# STM32G554 register map
File version: 2.0.0
CPU: CM33 r0p4, little endian, MPU, FPU, 4 interrupt priority bits
Registers are 32-bit, read-write, reset 0x0 unless marked. A register's access mark holds for its fields unless they carry their own. Offsets are from the block's base; [hi:lo] are bit positions; 'fields as' and 'values as' point back to an identical list.

## FDCAN1 — FDCAN register block
Base 0x4000A000
Same registers: FDCAN2 0x4000A400, FDCAN3 0x4000A800, FDCAN1_S 0x5000A000, FDCAN2_S 0x5000A400, FDCAN3_S 0x5000A800
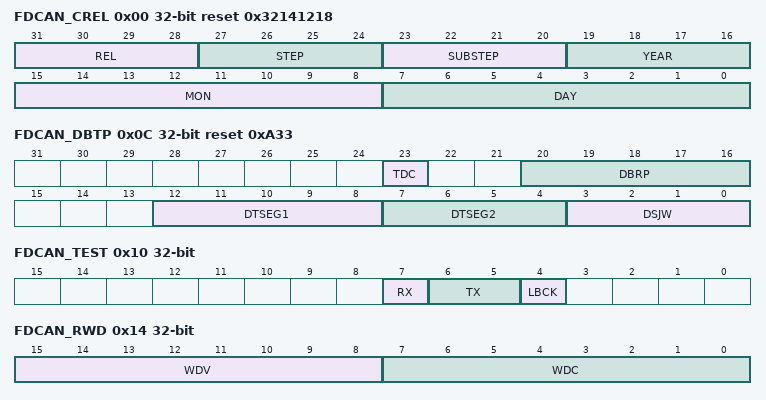
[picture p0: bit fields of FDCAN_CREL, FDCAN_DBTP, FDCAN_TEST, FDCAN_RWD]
0x00 FDCAN_CREL ro reset 0x32141218 — FDCAN core release register
  [31:28] REL — 3
  [27:24] STEP — 2
  [23:20] SUBSTEP — 1
  [19:16] YEAR — 4
  [15:8] MON — 12
  [7:0] DAY — 18
0x04 FDCAN_ENDN ro reset 0x87654321 — FDCAN endian register
  [31:0] ETV — Endianness test value
0x0C FDCAN_DBTP reset 0xA33 — FDCAN data bit timing and prescaler register
  [23] TDC — Transceiver delay compensation
    0=Transceiver delay compensation disabled; 1=Transceiver delay compensation enabled
  [20:16] DBRP — Data bit rate prescaler
  [12:8] DTSEG1 — Data time segment before sample point
  [7:4] DTSEG2 — Data time segment after sample point
  [3:0] DSJW — Synchronization jump width
0x10 FDCAN_TEST
  [7] RX ro — Receive pin
    0=The CAN bus is dominant (FDCANx_RX=0); 1=The CAN bus is recessive (FDCANx_RX=1)
  [6:5] TX — Control of transmit pin
    0=Reset value, FDCANx_TX TX is controlled by the CAN core, updated at the end of the CAN bit time; 1=Sample point can be monitored at pin FDCANx_TX; 2=Dominant (0) level at pin FDCANx_TX; 3=Recessive (1) at pin FDCANx_TX
  [4] LBCK — Loop-back mode
    0=Reset value, loop-back mode is disabled; 1=Loop-back mode is enabled (see Power-down (Sleep mode))
0x14 FDCAN_RWD — FDCAN RAM watchdog register
  [15:8] WDV ro — Watchdog value
  [7:0] WDC — Watchdog configuration
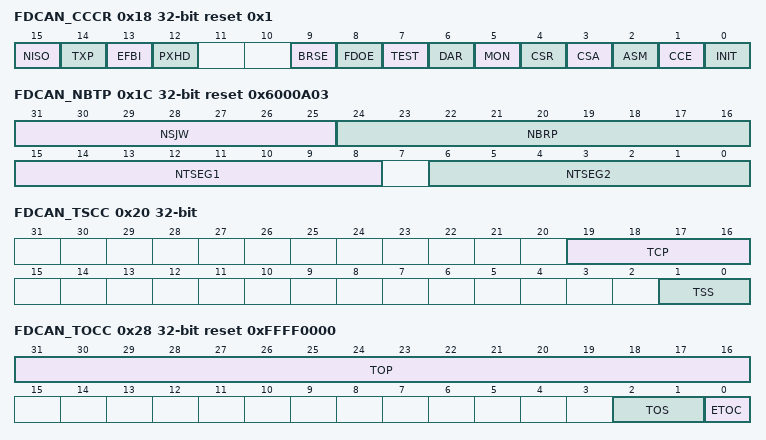
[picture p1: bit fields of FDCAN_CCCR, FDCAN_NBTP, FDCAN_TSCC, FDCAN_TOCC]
0x18 FDCAN_CCCR reset 0x1 — FDCAN CC control register
  [15] NISO — Non-ISO operation
    0=CAN FD frame format according to ISO11898-1; 1=CAN FD frame format according to Bosch CAN FD Specification V1.0
  [14] TXP — Transmit pause enable
    0=Disabled; 1=Enabled
  [13] EFBI — Edge filtering during bus integration
    0=Edge filtering disabled; 1=Two consecutive dominant tless thansub>qless than/sub> required to detect an edge for hard synchronization
  [12] PXHD — Protocol exception handling disable
    0=Protocol exception handling enabled; 1=Protocol exception handling disabled
  [9] BRSE — FDCAN bit rate switching
    0=Bit rate switching for transmissions disabled; 1=Bit rate switching for transmissions enabled
  [8] FDOE — FD operation enable
    0=FD operation disabled; 1=FD operation enabled
  [7] TEST — Test mode enable
    0=Normal operation, FDCAN_TEST holds reset values; 1=Test mode, write access to FDCAN_TEST enabled
  [6] DAR — Disable automatic retransmission
    0=Automatic retransmission of messages not transmitted successfully enabled; 1=Automatic retransmission disabled
  [5] MON — Bus monitoring mode
    0=Bus monitoring mode disabled; 1=Bus monitoring mode enabled
  [4] CSR — Clock stop request
    0=No clock stop requested; 1=Clock stop requested. When clock stop is requested, first INIT and then CSA is set after all pending transfer requests have been completed and the CAN bus is idle.
  [3] CSA ro — Clock stop acknowledge
    0=No clock stop acknowledged; 1=FDCAN can be set in power-down by stopping APB clock and kernel clock
  [2] ASM — ASM restricted operation mode
    0=Normal CAN operation; 1=Restricted operation mode active
  [1] CCE — Configuration change enable
    0=The CPU has no write access to the protected configuration registers; 1=The CPU has write access to the protected configuration registers (while INIT set in FDCAN_CCCR)
  [0] INIT — Initialization
    0=Normal operation; 1=Initialization started
0x1C FDCAN_NBTP reset 0x6000A03 — FDCAN nominal bit timing and prescaler register
  [31:25] NSJW — Nominal (re)synchronization jump width
  [24:16] NBRP — Bit rate prescaler
  [15:8] NTSEG1 — Nominal time segment before sample point
  [6:0] NTSEG2 — Nominal time segment after sample point
0x20 FDCAN_TSCC — FDCAN timestamp counter configuration register
  [19:16] TCP — Timestamp counter prescaler
  [1:0] TSS — Timestamp select
    0=Timestamp counter value always 0x0000; 1=Timestamp counter value incremented according to TCP; 2=External timestamp counter from TIM2 value (tim2_cnt[15:0]); 3=Same as 00
0x24 FDCAN_TSCV — FDCAN timestamp counter value register
  [15:0] TSC — Timestamp counter
0x28 FDCAN_TOCC reset 0xFFFF0000 — FDCAN timeout counter configuration register
  [31:16] TOP — Timeout period
  [2:1] TOS — Timeout select
    0=Continuous operation; 1=Timeout controlled by Tx event FIFO; 2=Timeout controlled by Rx FIFO 0; 3=Timeout controlled by Rx FIFO 1
  [0] ETOC — Timeout counter enable
    0=Timeout counter disabled; 1=Timeout counter enabled
0x2C FDCAN_TOCV reset 0xFFFF — FDCAN timeout counter value register
  [15:0] TOC — Timeout counter
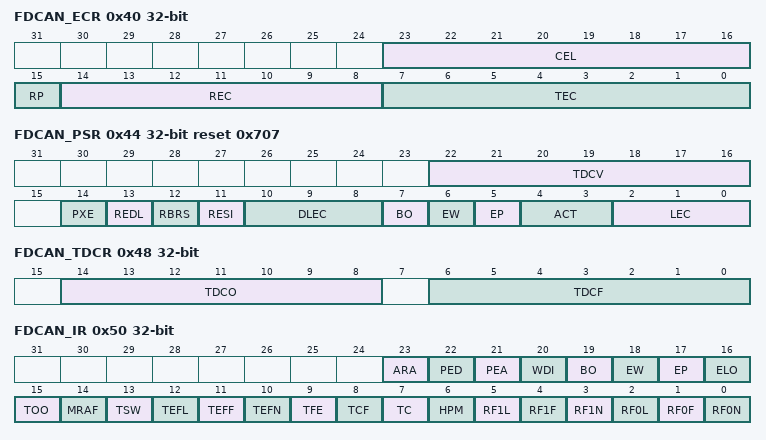
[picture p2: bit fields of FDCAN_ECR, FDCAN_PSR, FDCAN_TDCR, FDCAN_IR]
0x40 FDCAN_ECR — FDCAN error counter register
  [23:16] CEL — CAN error logging
  [15] RP ro — Receive error passive
    0=The receive error counter is below the error passive level of 128; 1=The receive error counter has reached the error passive level of 128
  [14:8] REC ro — Receive error counter
  [7:0] TEC ro — Transmit error counter
0x44 FDCAN_PSR reset 0x707 — FDCAN protocol status register
  [22:16] TDCV ro — Transmitter delay compensation value
  [14] PXE — Protocol exception event
    0=No protocol exception event occurred since last read access; 1=Protocol exception event occurred
  [13] REDL — Received FDCAN message
    0=Since this bit was cleared by the CPU, no FDCAN message has been received; 1=Message in FDCAN format with EDL flag set has been received
  [12] RBRS — BRS flag of last received FDCAN message
    0=Last received FDCAN message did not have its BRS flag set; 1=Last received FDCAN message had its BRS flag set
  [11] RESI — ESI flag of last received FDCAN message
    0=Last received FDCAN message did not have its ESI flag set; 1=Last received FDCAN message had its ESI flag set
  [10:8] DLEC — Data last error code
  [7] BO ro — Bus-off status
    0=The FDCAN is not in bus-off state; 1=The FDCAN is in bus-off state
  [6] EW ro — Warning status
    0=Both error counters are below the error-warning limit of 96; 1=At least one of error counter has reached the error-warning limit of 96
  [5] EP ro — Error passive
    0=The FDCAN is in the error-active state. It normally takes part in bus communication and sends an active error flag when an error has been detected.; 1=The FDCAN is in the error-passive state
  [4:3] ACT ro — Activity
    0=Synchronizing: node is synchronizing on CAN communication; 1=Idle: node is neither receiver nor transmitter; 2=Receiver: node is operating as receiver; 3=Transmitter: node is operating as transmitter
  [2:0] LEC — Last error code
    0=No error occurred since LEC[2:0] has been cleared by successful reception or transmission; 1=Stuff error. More than five equal bits in a sequence have occurred in a part of a received message where this is not allowed.; 2=Form error. A fixed format part of a received frame has the wrong format.; 3=Ack error. The message transmitted by the FDCAN was not acknowledged by another node.; 4=Bit1 error. During the transmission of a message (with the exception of the arbitration field), the device wanted to send a recessive level (bit of logical value 1), but the monitored bus value was dominant.; 5=Bit0 error. During the transmission of a message (or acknowledge bit, or active error flag, or overload flag), the device wanted to send a dominant level (data or identifier bit logical value 0), but the monitored bus value was recessive. During bus-off recovery this status is set each time a sequence of 11 recessive bits has been monitored. This enables the CPU to monitor the proceeding of the bus-off recovery sequence (indicating the bus is not stuck at dominant or continuously disturbed).; 6=CRC error. The CRC check sum of a received message was incorrect. The CRC of an incoming message does not match with the CRC calculated from the received data.; 7=No change. Any read access to the protocol status register reinitializes LEC[2:0] to 7. When the LEC[2:0] shows the value 7, no CAN bus event was detected since the last CPU read access to the protocol status register.
0x48 FDCAN_TDCR — FDCAN transmitter delay compensation register
  [14:8] TDCO — Transmitter delay compensation offset
  [6:0] TDCF — Transmitter delay compensation filter window length
0x50 FDCAN_IR — FDCAN interrupt register
  [23] ARA — Access to reserved address
    0=No access to reserved address occurred; 1=Access to reserved address occurred
  [22] PED — Protocol error in data phase (data bit time is used)
    0=No protocol error in data phase; 1=Protocol error in data phase detected (DLEC[2:0] different from 0 and 7 in FDCAN_PSR)
  [21] PEA — Protocol error in arbitration phase (nominal bit time is used)
    0=No protocol error in arbitration phase; 1=Protocol error in arbitration phase detected (LEC[2:0] different from 0 and 7 in FDCAN_PSR)
  [20] WDI — Watchdog interrupt
    0=No message RAM watchdog event occurred; 1=Message RAM watchdog event due to missing READY
  [19] BO — Bus-off status
    0=Bus-off status unchanged; 1=Bus-off status changed
  [18] EW — Warning status
    0=Error-warning status unchanged; 1=Error-warning status changed
  [17] EP — Error passive
    0=Error-passive status unchanged; 1=Error-passive status changed
  [16] ELO — Error logging overflow
    0=CAN error logging counter did not overflow; 1=Overflow of CAN error logging counter occurred
  [15] TOO — Timeout occurred
    0=No timeout; 1=Timeout reached
  [14] MRAF — Message RAM access failure
    0=No message RAM access failure occurred; 1=Message RAM access failure occurred
  [13] TSW — Timestamp wraparound
    0=No timestamp counter wrap-around; 1=Timestamp counter wrapped around
  [12] TEFL — Tx event FIFO element lost
    0=No Tx event FIFO element lost; 1=Tx event FIFO element lost
  [11] TEFF — Tx event FIFO full
    0=Tx event FIFO Not full; 1=Tx event FIFO full
  [10] TEFN — Tx event FIFO new entry
    0=Tx event FIFO unchanged; 1=Tx handler wrote Tx event FIFO element
  [9] TFE — Tx FIFO empty
    0=Tx FIFO non-empty; 1=Tx FIFO empty
  [8] TCF — Transmission cancellation finished
    0=No transmission cancellation finished; 1=Transmission cancellation finished
  [7] TC — Transmission completed
    0=No transmission completed; 1=Transmission completed
  [6] HPM — High-priority message
    0=No high-priority message received; 1=High-priority message received
  [5] RF1L — Rx FIFO 1 message lost
    0=No Rx FIFO 1 message lost; 1=Rx FIFO 1 message lost
  [4] RF1F — Rx FIFO 1 full
    0=Rx FIFO 1 not full; 1=Rx FIFO 1 full
  [3] RF1N — Rx FIFO 1 new message
    0=No new message written to Rx FIFO 1; 1=New message written to Rx FIFO 1
  [2] RF0L — Rx FIFO 0 message lost
    0=No Rx FIFO 0 message lost; 1=Rx FIFO 0 message lost
  [1] RF0F — Rx FIFO 0 full
    0=Rx FIFO 0 not full; 1=Rx FIFO 0 full
  [0] RF0N — Rx FIFO 0 new message
    0=No new message written to Rx FIFO 0; 1=New message written to Rx FIFO 0
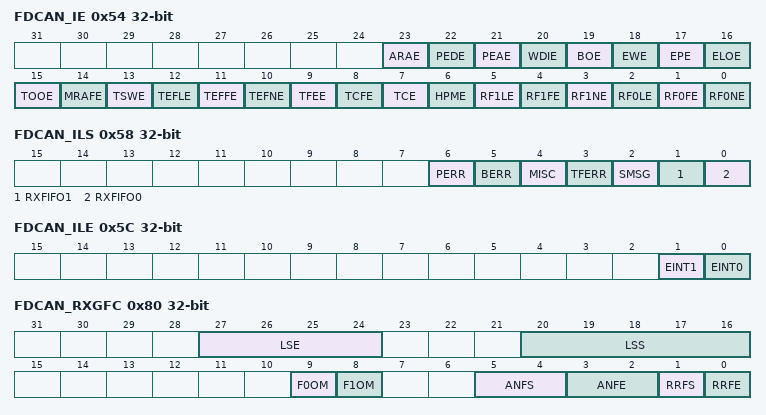
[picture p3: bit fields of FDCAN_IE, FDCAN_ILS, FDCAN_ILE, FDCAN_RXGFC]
0x54 FDCAN_IE — FDCAN interrupt enable register
  [23] ARAE — Access to reserved address enable
  [22] PEDE — Protocol error in data phase enable
  [21] PEAE — Protocol error in arbitration phase enable
  [20] WDIE — Watchdog interrupt enable
    0=Interrupt disabled; 1=Interrupt enabled
  [19] BOE — Bus-off status
    0=Interrupt disabled; 1=Interrupt enabled
  [18] EWE — Warning status interrupt enable
    0=Interrupt disabled; 1=Interrupt enabled
  [17] EPE — Error passive interrupt enable
    0=Interrupt disabled; 1=Interrupt enabled
  [16] ELOE — Error logging overflow interrupt enable
    0=Interrupt disabled; 1=Interrupt enabled
  [15] TOOE — Timeout occurred interrupt enable
    0=Interrupt disabled; 1=Interrupt enabled
  [14] MRAFE — Message RAM access failure interrupt enable
    0=Interrupt disabled; 1=Interrupt enabled
  [13] TSWE — Timestamp wraparound interrupt enable
    0=Interrupt disabled; 1=Interrupt enabled
  [12] TEFLE — Tx event FIFO element lost interrupt enable
    0=Interrupt disabled; 1=Interrupt enabled
  [11] TEFFE — Tx event FIFO full interrupt enable
    0=Interrupt disabled; 1=Interrupt enabled
  [10] TEFNE — Tx event FIFO new entry interrupt enable
    0=Interrupt disabled; 1=Interrupt enabled
  [9] TFEE — Tx FIFO empty interrupt enable
    0=Interrupt disabled; 1=Interrupt enabled
  [8] TCFE — Transmission cancellation finished interrupt enable
    0=Interrupt disabled; 1=Interrupt enabled
  [7] TCE — Transmission completed interrupt enable
    0=Interrupt disabled; 1=Interrupt enabled
  [6] HPME — High-priority message interrupt enable
    0=Interrupt disabled; 1=Interrupt enabled
  [5] RF1LE — Rx FIFO 1 message lost interrupt enable
    0=Interrupt disabled; 1=Interrupt enabled
  [4] RF1FE — Rx FIFO 1 full interrupt enable
    0=Interrupt disabled; 1=Interrupt enabled
  [3] RF1NE — Rx FIFO 1 new message interrupt enable
    0=Interrupt disabled; 1=Interrupt enabled
  [2] RF0LE — Rx FIFO 0 message lost interrupt enable
    0=Interrupt disabled; 1=Interrupt enabled
  [1] RF0FE — Rx FIFO 0 full interrupt enable
    0=Interrupt disabled; 1=Interrupt enabled
  [0] RF0NE — Rx FIFO 0 new message interrupt enable
    0=Interrupt disabled; 1=Interrupt enabled
0x58 FDCAN_ILS — FDCAN interrupt line select register
  [6] PERR — Protocol error grouping the following interruption
  [5] BERR — Bit and line error grouping the following interruption
  [4] MISC — Interrupt regrouping the following interruption
  [3] TFERR — Tx FIFO ERROR grouping the following interruption
  [2] SMSG — Status message bit grouping the following interruption
  [1] RXFIFO1 — RX FIFO bit grouping the following interruption
  [0] RXFIFO0 — RX FIFO bit grouping the following interruption
0x5C FDCAN_ILE — FDCAN interrupt line enable register
  [1] EINT1 — Enable interrupt line 1
    0=Interrupt line fdcan_intr0_it disabled; 1=Interrupt line fdcan_intr0_it enabled
  [0] EINT0 — Enable interrupt line 0
    0=Interrupt line fdcan_intr1_it disabled; 1=Interrupt line fdcan_intr1_it enabled
0x80 FDCAN_RXGFC — FDCAN global filter configuration register
  [27:24] LSE — Number of extended filter elements in the list
    0=No extended message ID filter
  [20:16] LSS — Number of standard filter elements in the list
    0=No standard message ID filter
  [9] F0OM — FIFO 0 operation mode (overwrite or blocking)
  [8] F1OM — FIFO 1 operation mode (overwrite or blocking)
  [5:4] ANFS — Accept Non-matching frames standard
    0=Accept in Rx FIFO 0; 1=Accept in Rx FIFO 1; 2=Reject; 3=Reject
  [3:2] ANFE — Accept non-matching frames extended
    values as ANFS
  [1] RRFS — Reject remote frames standard
    0=Filter remote frames with 11-bit standard IDs; 1=Reject all remote frames with 11-bit standard IDs
  [0] RRFE — Reject remote frames extended
    0=Filter remote frames with 29-bit standard IDs; 1=Reject all remote frames with 29-bit standard IDs
0x84 FDCAN_XIDAM reset 0x1FFFFFFF — FDCAN extended ID and mask register
  [28:0] EIDM — Extended ID mask
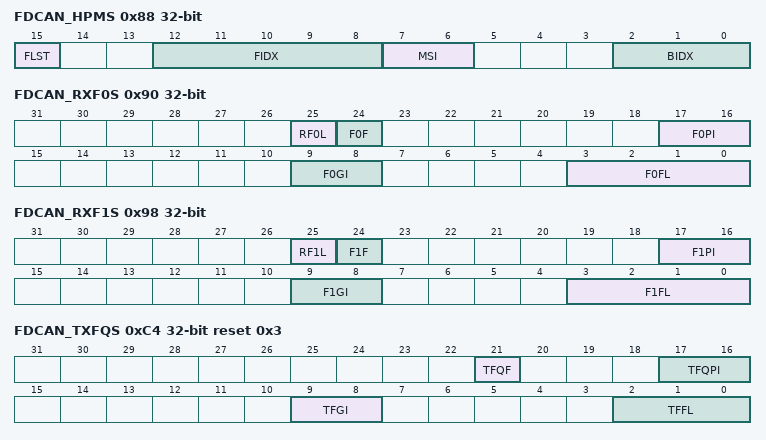
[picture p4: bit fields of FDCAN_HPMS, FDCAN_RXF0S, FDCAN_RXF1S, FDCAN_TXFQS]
0x88 FDCAN_HPMS ro — FDCAN high-priority message status register
  [15] FLST — Filter list
    0=Standard filter list; 1=Extended filter list
  [12:8] FIDX — Filter index
  [7:6] MSI — Message storage indicator
    0=No FIFO selected; 1=FIFO overrun; 2=Message stored in FIFO 0; 3=Message stored in FIFO 1
  [2:0] BIDX — Buffer index
0x90 FDCAN_RXF0S ro — FDCAN Rx FIFO 0 status register
  [25] RF0L — Rx FIFO 0 message lost
    0=No Rx FIFO 0 message lost; 1=Rx FIFO 0 message lost, also set after write attempt to Rx FIFO 0 of size 0
  [24] F0F — Rx FIFO 0 full
    0=Rx FIFO 0 not full; 1=Rx FIFO 0 full
  [17:16] F0PI — Rx FIFO 0 put index
  [9:8] F0GI — Rx FIFO 0 get index
  [3:0] F0FL — Rx FIFO 0 fill level
0x94 FDCAN_RXF0A — CAN Rx FIFO 0 acknowledge register
  [2:0] F0AI — Rx FIFO 0 acknowledge index
0x98 FDCAN_RXF1S ro — FDCAN Rx FIFO 1 status register
  [25] RF1L — Rx FIFO 1 message lost
    0=No Rx FIFO 1 message lost; 1=Rx FIFO 1 message lost, also set after write attempt to Rx FIFO 1 of size 0
  [24] F1F — Rx FIFO 1 full
    0=Rx FIFO 1 not full; 1=Rx FIFO 1 full
  [17:16] F1PI — Rx FIFO 1 put index
  [9:8] F1GI — Rx FIFO 1 get index
  [3:0] F1FL — Rx FIFO 1 fill level
0x9C FDCAN_RXF1A — FDCAN Rx FIFO 1 acknowledge register
  [2:0] F1AI — Rx FIFO 1 acknowledge index
0xC0 FDCAN_TXBC — FDCAN Tx buffer configuration register
  [24] TFQM — Tx FIFO/queue mode
    0=Tx FIFO operation; 1=Tx queue operation
0xC4 FDCAN_TXFQS ro reset 0x3 — FDCAN Tx FIFO/queue status register
  [21] TFQF — Tx FIFO/queue full
    0=Tx FIFO/queue not full; 1=Tx FIFO/queue full
  [17:16] TFQPI — Tx FIFO/queue put index
  [9:8] TFGI — Tx FIFO get index
  [2:0] TFFL — Tx FIFO free level
0xC8 FDCAN_TXBRP ro — FDCAN Tx buffer request pending register
  [2:0] TRP — Transmission request pending
    0=No transmission request pending; 1=Transmission request pending
0xCC FDCAN_TXBAR — FDCAN Tx buffer add request register
  [2:0] AR — Add request
    0=No transmission request added; 1=Transmission requested added
0xD0 FDCAN_TXBCR — FDCAN Tx buffer cancellation request register
  [2:0] CR — Cancellation request
    0=No cancellation pending; 1=Cancellation pending
0xD4 FDCAN_TXBTO ro — FDCAN Tx buffer transmission occurred register
  [2:0] TO — Transmission occurred.
    0=No transmission occurred; 1=Transmission occurred
0xD8 FDCAN_TXBCF ro — FDCAN Tx buffer cancellation finished register
  [2:0] CF — Cancellation finished
    0=No transmit buffer cancellation; 1=Transmit buffer cancellation finished
0xDC FDCAN_TXBTIE — FDCAN Tx buffer transmission interrupt enable register
  [2:0] TIE — Transmission interrupt enable
    0=Transmission interrupt disabled; 1=Transmission interrupt enable
0xE0 FDCAN_TXBCIE — FDCAN Tx buffer cancellation finished interrupt enable register
  [2:0] CFIE — Cancellation finished interrupt enable.
    0=Cancellation finished interrupt disabled; 1=Cancellation finished interrupt enabled
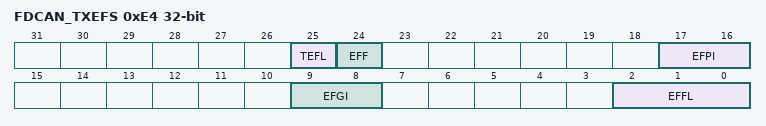
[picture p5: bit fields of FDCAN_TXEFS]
0xE4 FDCAN_TXEFS ro — FDCAN Tx event FIFO status register
  [25] TEFL — Tx event FIFO element lost
  [24] EFF — Event FIFO full
    0=Tx event FIFO not full; 1=Tx event FIFO full
  [17:16] EFPI — Event FIFO put index
  [9:8] EFGI — Event FIFO get index
  [2:0] EFFL — Event FIFO fill level
0xE8 FDCAN_TXEFA — FDCAN Tx event FIFO acknowledge register
  [1:0] EFAI — Event FIFO acknowledge index
0x100 FDCAN_CKDIV — FDCAN CFG clock divider register
  [3:0] PDIV — input clock divider
    0=Divide by 1; 1=Divide by 2; 2=Divide by 4; 3=Divide by 6; 4=Divide by 8; 5=Divide by 10; 6=Divide by 12; 7=Divide by 14; 8=Divide by 16; 9=Divide by 18; 10=Divide by 20; 11=Divide by 22; 12=Divide by 24; 13=Divide by 26; 14=Divide by 28; 15=Divide by 30
